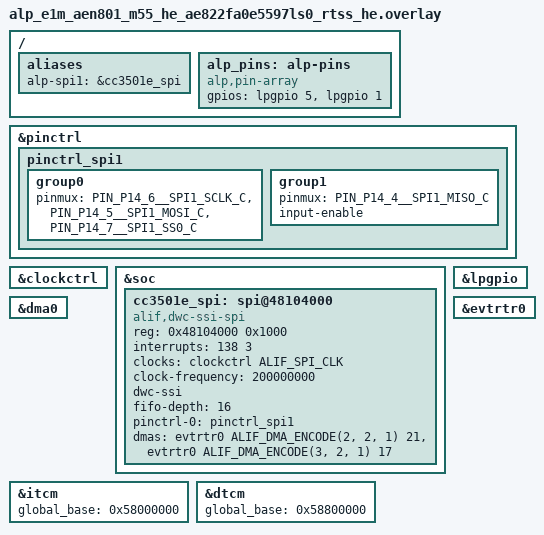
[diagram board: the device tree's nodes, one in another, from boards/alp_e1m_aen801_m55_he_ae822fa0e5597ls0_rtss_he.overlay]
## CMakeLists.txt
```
# SPDX-License-Identifier: Apache-2.0

cmake_minimum_required(VERSION 3.20)

find_package(Zephyr REQUIRED HINTS $ENV{ZEPHYR_BASE})
project(aen_cc3501e_gatt_register LANGUAGES C)

target_sources(app PRIVATE src/main.c)
# Reusable SoM bring-up helper (cc3501e_bridge_bringup): the one-call CC3501E
# bridge init the example + applications use. Copyable template -- see
# cc3501e_bridge.h. (Same helper as aen-cc3501e-companion-tour; examples are
# meant to be self-contained, copyable starting points.)
target_sources(app PRIVATE src/cc3501e_bridge.c)
```

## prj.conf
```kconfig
# SPDX-License-Identifier: Apache-2.0
#
# CONFIG_SPI / CONFIG_GPIO come from board.yaml's `peripherals:` block (via
# the generated alp.conf); CONFIG_RAM_CONSOLE + friends come from
# `diagnostics.console: ram` in the same file -- this file only carries what
# board.yaml has no knob for.
CONFIG_PRINTK=y
CONFIG_LOG=y

# The bench check does a handful of driver scratch buffers (GATT descriptor
# encode + the advertising payload) on the main thread; a generous stack
# keeps them comfortable.
CONFIG_MAIN_STACK_SIZE=4096

# Link the app at the HE MRAM app partition (0x80010000) so its vector table
# matches the ATOC load address (app-zephyr-he.json mramAddress=0x80010000).
# FLASH_BASE is the full MRAM (0x80000000); without this 0x10000 offset the
# image links at 0x80000000 and the SES boots it 64 KB low -> fault/no-boot.
CONFIG_FLASH_LOAD_OFFSET=0x10000
```

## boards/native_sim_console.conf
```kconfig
# SPDX-License-Identifier: Apache-2.0
#
# native_sim override for board.yaml's `diagnostics.console: ram` -- appended
# to EXTRA_CONF_FILE (see CMakeLists.txt) AFTER the generated alp.conf so it
# wins the merge, unlike boards/native_sim_native_64.conf (which Zephyr's own
# board-conf auto-discovery merges BEFORE alp.conf and would just get
# overridden right back to CONFIG_RAM_CONSOLE=y).
#
# native_sim genuinely cannot BUILD CONFIG_RAM_CONSOLE: Zephyr's
# drivers/console/ram_console.c unconditionally calls __stdout_hook_install(),
# and that symbol is only ever DEFINED by a libc integration layer gated
# `depends on !(NATIVE_LIBRARY && EXTERNAL_LIBC)` (lib/libc/Kconfig
# CONFIG_STDOUT_CONSOLE) -- native_sim always selects BOTH NATIVE_LIBRARY and
# EXTERNAL_LIBC, so that guard is always false and the symbol never exists,
# failing the link with "undefined reference to `__stdout_hook_install'".
# The real bench rig has no UART wired to USB, so the RAM console is correct
# there; this file only swaps it back to the native console for the
# native_sim build-only smoke target.
CONFIG_RAM_CONSOLE=n
CONFIG_UART_CONSOLE=y
```

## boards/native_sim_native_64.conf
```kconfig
# SPDX-License-Identifier: Apache-2.0
#
# native_sim has no real SPI controller; pull in the emul SPI driver so
# the alp-spi1 bus enumerates at boot.  Auto-loaded by Zephyr when
# building for native_sim/native/64.  (On the real AEN board the alp-spi1
# alias resolves to the dwc-ssi SPI1 controller instead -- see
# boards/alp_e1m_aen801_m55_he.overlay.)

CONFIG_EMUL=y
CONFIG_SPI_EMUL=y

# NOTE: the RAM-console override for board.yaml's `diagnostics.console: ram`
# is NOT here -- Zephyr's `boards/<board>.conf` auto-discovery merges THIS
# file BEFORE the generated alp.conf (EXTRA_CONF_FILE), so a Kconfig set
# here would just get overwritten by alp.conf's CONFIG_RAM_CONSOLE=y. See
# native_sim_console.conf (merged AFTER alp.conf via testcase.yaml extra_args;
# list it in EXTRA_CONF_FILE) for that override + the reason it's needed.
```

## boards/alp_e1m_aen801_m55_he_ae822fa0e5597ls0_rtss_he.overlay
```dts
/*
 * Copyright (c) 2026 Alp Lab AB
 * SPDX-License-Identifier: Apache-2.0
 *
 * Inter-chip wiring for the CC3501E bring-up on the E1M-AEN801 (Alif
 * Ensemble E8, M55-HE).  Declares the SoM-internal Alif<->CC3501E link:
 * the SPI1 master bus + the two host-driven control nets, all from
 * metadata/e1m_modules/aen/inter-chip.tsv:
 *
 *   SPI1.SCK  P14_6   SPI1.MOSI P14_5   SPI1.MISO P14_4   (-> CC3501E GPIO_27/28/29)
 *   WIFI_EN   P15_5 (lpgpio 5)          E_WIFI.NRST P15_1_FLEX (lpgpio 1)
 *
 * "P15" is the Alif low-power GPIO island (lpgpio @ 0x42002000); the
 * _FLEX pads are its pins.  P14 is a main-domain port used here purely as
 * the SPI1 function via pinctrl, so no gpio14 controller node is needed.
 *
 * BENCH-UNVERIFIED.  Like the rest of the alp-sdk Alif peripheral layer
 * (zephyr/dts/alif/ensemble_e8_peripherals.dtsi), the addresses/IRQs are
 * transcribed from the Apache-2.0 alifsemi/zephyr_alif fork + the AE822
 * TRM and have NOT been validated on silicon.  The SPI1 pinctrl macros are
 * RESOLVED against zephyr/dt-bindings/pinctrl/alif-ensemble-pinctrl.h
 * (SPI1 on P14_4/5/6 = alt-2, the `_C` suffix) and the LP-GPIO mux is the
 * reset default (alt-0 = LPGPIO); the one remaining genuine unknown is the
 * SPI1 IRQ number (upstream Zephyr declares no SPI node, so it is not in
 * the build tree) -- confirm it against the AE822 TRM before relying on
 * the interrupt-driven path on silicon.
 */

#include <zephyr/dt-bindings/pinctrl/alif-ensemble-pinctrl.h>
#include <zephyr/dt-bindings/gpio/gpio.h>
#include <zephyr/dt-bindings/dma/alif_dma_event_router.h>

&pinctrl {
	/*
	 * SPI1 master on P14_6 (SCK) / P14_5 (MOSI) / P14_4 (MISO).
	 *
	 * RESOLVED against alif-ensemble-pinctrl.h: the SPI1 functions on these
	 * three pads are alt-2, named with the `_C` suffix
	 * (PIN_P14_6__SPI1_SCLK_C = ALIF_PINMUX(14, 6, 2), etc.).  input-enable
	 * on MISO so the pad can sense the slave's drive (the same read-enable
	 * requirement the I2C pads need on this SoC).
	 */
	pinctrl_spi1: pinctrl_spi1 {
		group0 {
			/* Hardware SS0 chip-select (P14_7 = SPI1_SS0_C) -- dwc-ssi master
			 * drives SS0 per transfer to frame the CC3501E slave. */
			pinmux = <PIN_P14_6__SPI1_SCLK_C>, <PIN_P14_5__SPI1_MOSI_C>,
				 <PIN_P14_7__SPI1_SS0_C>;
		};
		group1 {
			pinmux = <PIN_P14_4__SPI1_MISO_C>;
			input-enable;
		};
	};
};

/*
 * DWC_ssi SPI1 (AHB) -- the on-SoM CC3501E inter-chip link.  Deliberately
 * NOT in ensemble_e8_peripherals.dtsi (that dtsi declares only the
 * customer-facing edge SPI0); this is the SoM-internal Wi-Fi link, so it
 * lives in the consuming app's overlay.  Same driver + flags as spi0
 * (compatible "alif,dwc-ssi-spi", dwc-ssi layout, fifo-depth 16,
 * frequency-only ALIF_SPI_CLK).
 *
 * reg 0x48104000 = SPI1 base (spi0 is 0x48103000, +0x1000/instance).
 * BENCH-TBD: interrupts = <138 3> follows the consecutive pattern from
 * spi0's IRQ 137 -- confirm SPI1_IRQ against the fork's e1.dtsi / TRM.
 *
 * No cs-gpios: P14_7 is muxed as SPI1_SS0_C above and the dwc-ssi peripheral
 * drives hardware SS0 per transfer.  The host opens ALP_SPI_NO_CS so no GPIO CS
 * is installed, allowing the SPI driver to use its hardware slave-select path.
 */
&clockctrl {
	status = "okay";
};

&soc {
	cc3501e_spi: spi@48104000 {
		compatible = "alif,dwc-ssi-spi";
		#address-cells = <1>;
		#size-cells = <0>;
		reg = <0x48104000 0x1000>;
		interrupts = <138 3>;          /* BENCH-TBD: confirm SPI1 IRQ */
		clocks = <&clockctrl ALIF_SPI_CLK>;
		/*
		 * ROOT-CAUSE FIX 2026-06-16: spi_dw_alif's configure takes the
		 * clock-control path when no clock-frequency is set, and that path
		 * fails (-EINVAL) for the gateless dummy ALIF_SPI_CLK -> every
		 * transceive returned ALP_ERR_INVAL with zero SCLK (witness fail_step=1,
		 * zerr=-EINVAL). Providing the SSI input clock here makes the driver
		 * use it directly and skip the failing clock-control path. SYST_HCLK =
		 * AHB = 400 MHz (E8 HWRM); BAUDR = 400M/freq_hz (=50 for an 8 MHz SCLK).
		 */
		clock-frequency = <200000000>; /* real SSI functional clock (was mis-set 400M; proven via BAUDR scaling) */
		dwc-ssi;
		fifo-depth = <16>;
		pinctrl-0 = <&pinctrl_spi1>;
		pinctrl-names = "default";
		status = "okay";
	};
};

/*
 * Enable the LP GPIO island so WIFI_EN (P15_5) and E_WIFI.NRST
 * (P15_1_FLEX) are drivable as outputs.  gpio_dw needs no clocks/pinctrl
 * on the controller, and the pad->GPIO mux needs no pinctrl group either:
 * RESOLVED against alif-ensemble-pinctrl.h -- P15_1/P15_5 function 0 (the
 * reset default) IS LPGPIO (PIN_P15_x__LPGPIO = ALIF_PINMUX(15, x, 0)).
 */
&lpgpio {
	status = "okay";
};

/* P2_6 (E1M AH7 / I2S1_SCLK) is NOT the CC3501E READY net on the R2 module this
 * bridge targets -- it is E1M pad AH7 / I2S1_SCLK, which the E1M EVK carrier
 * repurposes as the Arduino header's CK_RST (metadata/boards/e1m-evk.yaml);
 * the real READY net lands on E1M pad G3 / IO16 instead
 * (metadata/e1m_modules/aen/from-cc3501e.tsv). This app therefore does not
 * enable &gpio2 or claim P2_6 as READY -- see src/cc3501e_bridge.c and
 * chips/cc3501e/cc3501e_core.c's cc3501e_reply_gate() comment. A board (or a
 * hand-reworked r1 unit) that genuinely wires GPIO17 to P2_6 can opt back
 * in: enable &gpio2, add a pinctrl group that enables P2_6's INPUT BUFFER --
 * reset-default mux already IS GPIO, but GPIO function alone does not enable
 * the input path; skip that group and cc3501e_reply_gate()'s read comes back
 * a constant 0 forever, indistinguishable from a stuck-LOW pad -- add an
 * alp_pins entry for it, and set fw->ready_pin in cc3501e_bridge_bringup(). */

/*
 * Host-side peripheral DMA for continuous SPI streams over the CC3501E bridge.
 * SPI1 is a MAIN-domain peripheral, so per the AE822 DFP soc_dma_map (SPI1_DMA=0,
 * group 2, TX req 21 / RX req 17) it routes through the SYSTOP DMA0 via its event
 * router evtrtr0 (4 groups -> group 2 valid) -- NOT the M55-HE-local DMA2/evtrtr2
 * (1 group, for LP peripherals; wiring SPI1 there leaves the channel Waiting-For-
 * Peripheral forever -- SPI1's request line isn't on the HE router).  DMA0's clock
 * is SYSTOP (already on -- the app drives SPI1/GPIO in the same region); its
 * PL330 boot-manager security latch (CLKCTRL_PER_MST) is in dma_alif_boot_latch.c.
 * The fork PL330 driver statically allocates the per-channel ucode + remaps it via
 * local_to_global(), so no external `microcode` prop is needed.
 *
 * dma0 + evtrtr0 are now declared in ensemble_e8_peripherals.dtsi (disabled
 * by default, alp-sdk issue #1815); this overlay only enables them.
 */
&dma0 {
	status = "okay";
};

&evtrtr0 {
	status = "okay";
};

/*
 * Route the bridge SPI1 through evtrtr0 to DMA0.  Cell encoding
 * (ALIF_DMA_ENCODE(channel, dma_group, handshake), periph_req):
 *   TX = PL330 ch2, evtrtr group 2, handshake on, SPI1 TX periph req 21
 *   RX = PL330 ch3, evtrtr group 2, handshake on, SPI1 RX periph req 17
 * (AE822 DFP soc_dma_map.h: SPI1 group 2, TX 21 / RX 17.)
 */
&cc3501e_spi {
	dmas = <&evtrtr0 ALIF_DMA_ENCODE(2, 2, 1) 21>,
	       <&evtrtr0 ALIF_DMA_ENCODE(3, 2, 1) 17>;
	dma-names = "txdma", "rxdma";
};

/ {
	aliases {
		/* bus_id 1 in alp_spi_open() -> this controller. */
		alp-spi1 = &cc3501e_spi;
	};

	/*
	 * Compact 2-entry control array for the SoM-internal CC3501E control
	 * nets, in the order the app's CC3501E_PIN_* indices expect.  These are
	 * NOT E1M edge pads, so this bring-up app intentionally does NOT use the
	 * 52-slot positional E1M map; a production board file appends such
	 * SoM-internal control nets after the E1M pad slots.  No READY entry
	 * here -- see the P2_6 comment above &gpio2's removal further up.
	 */
	alp_pins: alp-pins {
		compatible = "alp,pin-array";
		gpios = <&lpgpio 5 GPIO_ACTIVE_HIGH>, /* [0] WIFI_EN     (P15_5)      */
			<&lpgpio 1 GPIO_ACTIVE_HIGH>; /* [1] E_WIFI.NRST (P15_1_FLEX) */
	};
};

/*
 * Global-bus aliases of the M55-HE TCMs, needed by hal_alif soc_memory_map.h
 * local_to_global() -- the PL330 (AXI master) reaches TCM-resident buffers only
 * via these global windows.  Values from the AE822 M55-HE map (sdk-alif fork
 * ensemble_rtss_he.dtsi): ITCM 0x0->0x58000000, DTCM 0x20000000->0x58800000.
 * (DMA stream buffers still belong in SRAM0 0x02000000, which is already global
 * -> local_to_global() returns it unchanged.)
 */
&itcm {
	global_base = <0x58000000>;
};
&dtcm {
	global_base = <0x58800000>;
};
```

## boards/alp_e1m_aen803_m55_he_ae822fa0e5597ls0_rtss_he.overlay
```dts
/*
 * Copyright (c) 2026 Alp Lab AB
 * SPDX-License-Identifier: Apache-2.0
 *
 * Inter-chip wiring for the CC3501E bring-up on the E1M-AEN803 (Alif
 * Ensemble E8, M55-HE).  Declares the SoM-internal Alif<->CC3501E link:
 * the SPI1 master bus + the two host-driven control nets, all from
 * metadata/e1m_modules/aen/inter-chip.tsv:
 *
 *   SPI1.SCK  P14_6   SPI1.MOSI P14_5   SPI1.MISO P14_4   (-> CC3501E GPIO_27/28/29)
 *   WIFI_EN   P15_5 (lpgpio 5)          E_WIFI.NRST P15_1_FLEX (lpgpio 1)
 *
 * "P15" is the Alif low-power GPIO island (lpgpio @ 0x42002000); the
 * _FLEX pads are its pins.  P14 is a main-domain port used here purely as
 * the SPI1 function via pinctrl, so no gpio14 controller node is needed.
 *
 * BENCH-UNVERIFIED.  Like the rest of the alp-sdk Alif peripheral layer
 * (zephyr/dts/alif/ensemble_e8_peripherals.dtsi), the addresses/IRQs are
 * transcribed from the Apache-2.0 alifsemi/zephyr_alif fork + the AE822
 * TRM and have NOT been validated on silicon.  The SPI1 pinctrl macros are
 * RESOLVED against zephyr/dt-bindings/pinctrl/alif-ensemble-pinctrl.h
 * (SPI1 on P14_4/5/6 = alt-2, the `_C` suffix) and the LP-GPIO mux is the
 * reset default (alt-0 = LPGPIO); the one remaining genuine unknown is the
 * SPI1 IRQ number (upstream Zephyr declares no SPI node, so it is not in
 * the build tree) -- confirm it against the AE822 TRM before relying on
 * the interrupt-driven path on silicon.
 */

#include <zephyr/dt-bindings/pinctrl/alif-ensemble-pinctrl.h>
#include <zephyr/dt-bindings/gpio/gpio.h>
#include <zephyr/dt-bindings/dma/alif_dma_event_router.h>

&pinctrl {
	/*
	 * SPI1 master on P14_6 (SCK) / P14_5 (MOSI) / P14_4 (MISO).
	 *
	 * RESOLVED against alif-ensemble-pinctrl.h: the SPI1 functions on these
	 * three pads are alt-2, named with the `_C` suffix
	 * (PIN_P14_6__SPI1_SCLK_C = ALIF_PINMUX(14, 6, 2), etc.).  input-enable
	 * on MISO so the pad can sense the slave's drive (the same read-enable
	 * requirement the I2C pads need on this SoC).
	 */
	pinctrl_spi1: pinctrl_spi1 {
		group0 {
			/* Hardware SS0 chip-select (P14_7 = SPI1_SS0_C) -- dwc-ssi master
			 * drives SS0 per transfer to frame the CC3501E slave. */
			pinmux = <PIN_P14_6__SPI1_SCLK_C>, <PIN_P14_5__SPI1_MOSI_C>,
				 <PIN_P14_7__SPI1_SS0_C>;
		};
		group1 {
			pinmux = <PIN_P14_4__SPI1_MISO_C>;
			input-enable;
		};
	};
};

/*
 * DWC_ssi SPI1 (AHB) -- the on-SoM CC3501E inter-chip link.  Deliberately
 * NOT in ensemble_e8_peripherals.dtsi (that dtsi declares only the
 * customer-facing edge SPI0); this is the SoM-internal Wi-Fi link, so it
 * lives in the consuming app's overlay.  Same driver + flags as spi0
 * (compatible "alif,dwc-ssi-spi", dwc-ssi layout, fifo-depth 16,
 * frequency-only ALIF_SPI_CLK).
 *
 * reg 0x48104000 = SPI1 base (spi0 is 0x48103000, +0x1000/instance).
 * BENCH-TBD: interrupts = <138 3> follows the consecutive pattern from
 * spi0's IRQ 137 -- confirm SPI1_IRQ against the fork's e1.dtsi / TRM.
 *
 * No cs-gpios: P14_7 is muxed as SPI1_SS0_C above and the dwc-ssi peripheral
 * drives hardware SS0 per transfer.  The host opens ALP_SPI_NO_CS so no GPIO CS
 * is installed, allowing the SPI driver to use its hardware slave-select path.
 */
&clockctrl {
	status = "okay";
};

&soc {
	cc3501e_spi: spi@48104000 {
		compatible = "alif,dwc-ssi-spi";
		#address-cells = <1>;
		#size-cells = <0>;
		reg = <0x48104000 0x1000>;
		interrupts = <138 3>;          /* BENCH-TBD: confirm SPI1 IRQ */
		clocks = <&clockctrl ALIF_SPI_CLK>;
		/*
		 * ROOT-CAUSE FIX 2026-06-16: spi_dw_alif's configure takes the
		 * clock-control path when no clock-frequency is set, and that path
		 * fails (-EINVAL) for the gateless dummy ALIF_SPI_CLK -> every
		 * transceive returned ALP_ERR_INVAL with zero SCLK (witness fail_step=1,
		 * zerr=-EINVAL). Providing the SSI input clock here makes the driver
		 * use it directly and skip the failing clock-control path. SYST_HCLK =
		 * AHB = 400 MHz (E8 HWRM); BAUDR = 400M/freq_hz (=50 for an 8 MHz SCLK).
		 */
		clock-frequency = <200000000>; /* real SSI functional clock (was mis-set 400M; proven via BAUDR scaling) */
		dwc-ssi;
		fifo-depth = <16>;
		pinctrl-0 = <&pinctrl_spi1>;
		pinctrl-names = "default";
		status = "okay";
	};
};

/*
 * Enable the LP GPIO island so WIFI_EN (P15_5) and E_WIFI.NRST
 * (P15_1_FLEX) are drivable as outputs.  gpio_dw needs no clocks/pinctrl
 * on the controller, and the pad->GPIO mux needs no pinctrl group either:
 * RESOLVED against alif-ensemble-pinctrl.h -- P15_1/P15_5 function 0 (the
 * reset default) IS LPGPIO (PIN_P15_x__LPGPIO = ALIF_PINMUX(15, x, 0)).
 */
&lpgpio {
	status = "okay";
};

/* P2_6 (E1M AH7 / I2S1_SCLK) is NOT the CC3501E READY net on the R2 module this
 * bridge targets -- it is E1M pad AH7 / I2S1_SCLK, which the E1M EVK carrier
 * repurposes as the Arduino header's CK_RST (metadata/boards/e1m-evk.yaml);
 * the real READY net lands on E1M pad G3 / IO16 instead
 * (metadata/e1m_modules/aen/from-cc3501e.tsv). This app therefore does not
 * enable &gpio2 or claim P2_6 as READY -- see src/cc3501e_bridge.c and
 * chips/cc3501e/cc3501e_core.c's cc3501e_reply_gate() comment. A board (or a
 * hand-reworked r1 unit) that genuinely wires GPIO17 to P2_6 can opt back
 * in: enable &gpio2, add a pinctrl group that enables P2_6's INPUT BUFFER --
 * reset-default mux already IS GPIO, but GPIO function alone does not enable
 * the input path; skip that group and cc3501e_reply_gate()'s read comes back
 * a constant 0 forever, indistinguishable from a stuck-LOW pad -- add an
 * alp_pins entry for it, and set fw->ready_pin in cc3501e_bridge_bringup(). */

/*
 * Host-side peripheral DMA for continuous SPI streams over the CC3501E bridge.
 * SPI1 is a MAIN-domain peripheral, so per the AE822 DFP soc_dma_map (SPI1_DMA=0,
 * group 2, TX req 21 / RX req 17) it routes through the SYSTOP DMA0 via its event
 * router evtrtr0 (4 groups -> group 2 valid) -- NOT the M55-HE-local DMA2/evtrtr2
 * (1 group, for LP peripherals; wiring SPI1 there leaves the channel Waiting-For-
 * Peripheral forever -- SPI1's request line isn't on the HE router).  DMA0's clock
 * is SYSTOP (already on -- the app drives SPI1/GPIO in the same region); its
 * PL330 boot-manager security latch (CLKCTRL_PER_MST) is in dma_alif_boot_latch.c.
 * The fork PL330 driver statically allocates the per-channel ucode + remaps it via
 * local_to_global(), so no external `microcode` prop is needed.
 *
 * dma0 + evtrtr0 are now declared in ensemble_e8_peripherals.dtsi (disabled
 * by default, alp-sdk issue #1815); this overlay only enables them.
 */
&dma0 {
	status = "okay";
};

&evtrtr0 {
	status = "okay";
};

/*
 * Route the bridge SPI1 through evtrtr0 to DMA0.  Cell encoding
 * (ALIF_DMA_ENCODE(channel, dma_group, handshake), periph_req):
 *   TX = PL330 ch2, evtrtr group 2, handshake on, SPI1 TX periph req 21
 *   RX = PL330 ch3, evtrtr group 2, handshake on, SPI1 RX periph req 17
 * (AE822 DFP soc_dma_map.h: SPI1 group 2, TX 21 / RX 17.)
 */
&cc3501e_spi {
	dmas = <&evtrtr0 ALIF_DMA_ENCODE(2, 2, 1) 21>,
	       <&evtrtr0 ALIF_DMA_ENCODE(3, 2, 1) 17>;
	dma-names = "txdma", "rxdma";
};

/ {
	aliases {
		/* bus_id 1 in alp_spi_open() -> this controller. */
		alp-spi1 = &cc3501e_spi;
	};

	/*
	 * Compact 2-entry control array for the SoM-internal CC3501E control
	 * nets, in the order the app's CC3501E_PIN_* indices expect.  These are
	 * NOT E1M edge pads, so this bring-up app intentionally does NOT use the
	 * 52-slot positional E1M map; a production board file appends such
	 * SoM-internal control nets after the E1M pad slots.  No READY entry
	 * here -- see the P2_6 comment above &gpio2's removal further up.
	 */
	alp_pins: alp-pins {
		compatible = "alp,pin-array";
		gpios = <&lpgpio 5 GPIO_ACTIVE_HIGH>, /* [0] WIFI_EN     (P15_5)      */
			<&lpgpio 1 GPIO_ACTIVE_HIGH>; /* [1] E_WIFI.NRST (P15_1_FLEX) */
	};
};

/*
 * Global-bus aliases of the M55-HE TCMs, needed by hal_alif soc_memory_map.h
 * local_to_global() -- the PL330 (AXI master) reaches TCM-resident buffers only
 * via these global windows.  Values from the AE822 M55-HE map (sdk-alif fork
 * ensemble_rtss_he.dtsi): ITCM 0x0->0x58000000, DTCM 0x20000000->0x58800000.
 * (DMA stream buffers still belong in SRAM0 0x02000000, which is already global
 * -> local_to_global() returns it unchanged.)
 */
&itcm {
	global_base = <0x58000000>;
};
&dtcm {
	global_base = <0x58800000>;
};
```

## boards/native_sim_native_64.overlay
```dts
/*
 * Copyright 2026 Alp Lab AB
 * SPDX-License-Identifier: Apache-2.0
 *
 * Host-emulated stand-ins for aen-cc3501e-bringup under native_sim, so the
 * example builds in CI (twister build_only) with no silicon.
 *
 *   - alp-spi1  -> an emulated SPI controller (no slave attached, so the
 *                  transceive path runs but reads back 0x00; the build, not
 *                  a live round-trip, is what this target proves).
 *   - alp,pin-array -> the two SoM-internal CC3501E control nets, in the
 *                  SAME order the app's CC3501E_PIN_* indices expect:
 *                    [0] WIFI_EN  (Alif P15_5)
 *                    [1] E_WIFI.NRST (Alif P15_1_FLEX)
 *                  This bring-up app uses its own compact 2-pin control
 *                  array (these nets are not E1M edge pads), not the 52-slot
 *                  positional E1M map the portable IO examples use.
 */

#include <zephyr/dt-bindings/gpio/gpio.h>

/ {
    aliases {
        alp-spi1 = &spi1_emul;
    };

    gpio_emul0: gpio_emul0 {
        compatible = "zephyr,gpio-emul";
        status = "okay";
        gpio-controller;
        rising-edge;
        falling-edge;
        #gpio-cells = <2>;
        ngpios = <8>;
    };

    alp_pins: alp-pins {
        compatible = "alp,pin-array";
        gpios = <&gpio_emul0 5 GPIO_ACTIVE_HIGH>,   /* [0] WIFI_EN     (P15_5)      */
                <&gpio_emul0 1 GPIO_ACTIVE_HIGH>;   /* [1] E_WIFI.NRST (P15_1_FLEX) */
    };

    soc {
        spi1_emul: spi@200 {
            compatible = "zephyr,spi-emul-controller";
            status = "okay";
            reg = <0 0x200 4>;
            #address-cells = <1>;
            #size-cells = <0>;
        };
    };
};
```

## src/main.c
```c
/*
 * Copyright 2026 Alp Lab AB
 * SPDX-License-Identifier: Apache-2.0
 *
 * aen-cc3501e-gatt-register -- bench check for the NEW CC3501E dynamic GATT
 * registration path (#480/#892) on the Alif Ensemble E8 (M55-HE).
 *
 * WHAT CHANGED UPSTREAM.  `alp_ble_gatt_register_service()` used to be a
 * stub; on this branch it really registers a service on the CC3501E's
 * NimBLE host over the inter-chip bridge and fills in a real attribute
 * handle per characteristic.  This app is the on-silicon proof, run
 * PEER-FREE -- there is no BLE central on the bench, so it cannot do full
 * central-side service discovery.  What it CAN prove without a peer:
 *
 *   1. registration returns real (non-zero) handles -- the registration
 *      itself worked, not just "the call didn't crash";
 *   2. the bridge is still alive and answering AFTER registration -- the
 *      on-silicon check for a NimBLE double-`ble_gatts_start()` use-after-
 *      free that the register path used to trigger (now fixed by resetting
 *      the GATT table via a single `ble_gatts_start()` per register, not a
 *      stray extra call);
 *   3. the register-then-advertise ORDERING GUARD: NimBLE's
 *      `ble_gatts_mutable()` refuses to re-run `ble_gatts_start()` once the
 *      stack is advertising/scanning/connected, so a SECOND register call
 *      issued while advertising must come back `ALP_ERR_BUSY` (see the
 *      @note on `alp_ble_gatt_register_service()` in <alp/ble.h>, and the
 *      wire-level remap comment in chips/cc3501e/cc3501e_ble.c).
 *
 * Full central-side verification (a real central connecting and reading
 * the two characteristics by their discovered handles) is HIL-deferred --
 * it needs a second BLE radio on the bench, which this rig does not have.
 *
 * THE SIX-STEP PASS CONTRACT (order matters -- register must precede
 * advertise, per the @note above):
 *
 *   1. cc3501e_bridge_bringup() + PING -> ALP_OK           (bridge ready)
 *   2. alp_ble_open()            -> non-NULL               (BLE enabled)
 *   3. alp_ble_gatt_register_service() (2 chars)
 *        -> ALP_OK AND both handles non-zero                (registered)
 *   4. a second bridge round-trip (PING) post-register
 *        -> still ALP_OK                                    (UAF-fix check)
 *   5. alp_ble_advertise_start() (<=8-char name)
 *        -> ALP_OK                                          (advertising)
 *   6. alp_ble_gatt_register_service() AGAIN, while advertising
 *        -> ALP_ERR_BUSY                                     (ordering guard)
 *
 * A single `RESULT PASS: ...` line means every step above held; the first
 * step that didn't prints `RESULT FAIL: <which step>` and the app stops --
 * this is a bench GATE, unlike the companion-tour's guarded non-fatal demo
 * steps.
 *
 * Console is the RAM buffer `ram_console_buf` (board.yaml `diagnostics.console:
 * ram`); this bench rig has no UART wired to USB.  BENCH-VALIDATION app --
 * not a customer teaching example (see aen-cc3501e-companion-tour for that).
 *
 * This file is ~50% comment by design: examples are documentation, and a
 * bench-gate app doubles as the readable spec of what "the fix works" means.
 */

#include <stdbool.h>
#include <stdio.h>

#include <zephyr/kernel.h> /* k_uptime_get() -- step-6 fast-path timing */

#include "alp/ble.h"
#include "alp/chips/cc3501e.h"
#include "alp/peripheral.h"

#include "cc3501e_bridge.h" /* cc3501e_bridge_bringup() -- the SoM bring-up helper */

/* Poll-by-repeat budgets.  PING is cheap + direct (see cc3501e_ping's doc);
 * a handful of retries absorbs residual boot/ramp jitter after
 * cc3501e_bridge_bringup() already waited out the fixed boot budget. */
#define GATT_PING_RETRIES 25u
#define GATT_PING_GAP_MS  200u

/*
 * Example-only vendor 128-bit service + characteristic UUIDs (bytes are
 * little-endian per alp_ble_uuid_t's doc comment).  These are NOT a
 * registered BT-SIG UUID -- a real product picks its own random 128-bit
 * UUID per service (e.g. `uuidgen`).  Three distinct UUIDs, one per
 * service/characteristic, differing only in the last two bytes so the
 * relationship is easy to eyeball in a hex dump.
 */
static const alp_ble_uuid_t GATT_SVC_UUID = { .b = { 0x01,
	                                                 0x02,
	                                                 0x03,
	                                                 0x04,
	                                                 0x05,
	                                                 0x06,
	                                                 0x07,
	                                                 0x08,
	                                                 0x09,
	                                                 0x0a,
	                                                 0x0b,
	                                                 0x0c,
	                                                 0x0d,
	                                                 0x0e,
	                                                 0xa0,
	                                                 0xa1 } };

static const alp_ble_uuid_t GATT_CHR_RO_UUID = { .b = { 0x01,
	                                                    0x02,
	                                                    0x03,
	                                                    0x04,
	                                                    0x05,
	                                                    0x06,
	                                                    0x07,
	                                                    0x08,
	                                                    0x09,
	                                                    0x0a,
	                                                    0x0b,
	                                                    0x0c,
	                                                    0x0d,
	                                                    0x0e,
	                                                    0xb0,
	                                                    0xb1 } };

static const alp_ble_uuid_t GATT_CHR_NOTIFY_UUID = { .b = { 0x01,
	                                                        0x02,
	                                                        0x03,
	                                                        0x04,
	                                                        0x05,
	                                                        0x06,
	                                                        0x07,
	                                                        0x08,
	                                                        0x09,
	                                                        0x0a,
	                                                        0x0b,
	                                                        0x0c,
	                                                        0x0d,
	                                                        0x0e,
	                                                        0xc0,
	                                                        0xc1 } };

/* Small initial values -- just enough bytes to prove the descriptor encode
 * (chips/cc3501e/cc3501e_ble.c's cc35_gatt_register_service) round-trips
 * non-empty payloads, not a real sensor reading. */
static const uint8_t GATT_REG_RO_INITIAL[]     = { 0x2a };
static const uint8_t GATT_REG_NOTIFY_INITIAL[] = { 0x00 };

/* Step: PING until the coprocessor answers (or the retry budget elapses).
 * Used both for the initial link-up check (step 1) and the post-register
 * liveness check (step 4) -- same helper, different meaning at each call
 * site (see the call sites below). */
static bool gatt_ping(cc3501e_t *fw)
{
	for (unsigned i = 0u; i < GATT_PING_RETRIES; ++i) {
		if (cc3501e_ping(fw) == ALP_OK) {
			return true;
		}
		alp_delay_ms(GATT_PING_GAP_MS);
	}
	return false;
}

int main(void)
{
	printf("\n[gatt-register] E1M-AEN CC3501E dynamic GATT registration bench check\n");

	/* ---- Step 1: bridge bring-up + PING -------------------------------- */
	cc3501e_t    fw;
	alp_status_t s = cc3501e_bridge_bringup(&fw);
	if (s != ALP_OK) {
		printf("RESULT FAIL: step 1 bridge bring-up -> %s (check WIFI_EN/SPI1 wiring)\n",
		       alp_status_name(s));
		return 0;
	}
	if (!gatt_ping(&fw)) {
		printf("RESULT FAIL: step 1 PING never answered after bring-up\n");
		return 0;
	}
	printf("[gatt-register] step 1 OK: bridge up + PING answered\n");

	/* ---- Step 2: alp_ble_open() ----------------------------------------
	 * The CC3501E BLE backend's open() (src/backends/ble/cc3501e.c
	 * cc35_open) calls cc3501e_ble_enable() on the first reference, which
	 * starts the firmware's shared-HIF Wi-Fi stack then the NimBLE host --
	 * a non-NULL return here means BOTH came up. */
	alp_ble_t *ble = alp_ble_open();
	if (ble == NULL) {
		printf("RESULT FAIL: step 2 alp_ble_open() -> NULL (err=%s)\n",
		       alp_status_name(alp_last_error()));
		return 0;
	}
	printf("[gatt-register] step 2 OK: alp_ble_open() -> %p (BLE controller + NimBLE up)\n",
	       (void *)ble);

	/* ---- Step 3: register a 2-characteristic service --------------------
	 * READ char first (a passive attribute), READ|NOTIFY second (the one a
	 * real central would subscribe to). Register-before-advertise is the
	 * hard ordering rule this whole app exists to prove -- see the file
	 * banner. A non-zero handle in BOTH slots is the only proof (short of a
	 * central connecting) that the firmware's NimBLE host actually built
	 * GATT attribute-table entries instead of silently no-op'ing. */
	alp_ble_char_def_t chars[2] = {
		{
		    .uuid          = GATT_CHR_RO_UUID,
		    .properties    = ALP_BLE_GATT_PROP_READ,
		    .initial_value = GATT_REG_RO_INITIAL,
		    .initial_len   = sizeof(GATT_REG_RO_INITIAL),
		},
		{
		    .uuid          = GATT_CHR_NOTIFY_UUID,
		    .properties    = ALP_BLE_GATT_PROP_READ | ALP_BLE_GATT_PROP_NOTIFY,
		    .initial_value = GATT_REG_NOTIFY_INITIAL,
		    .initial_len   = sizeof(GATT_REG_NOTIFY_INITIAL),
		},
	};
	alp_ble_service_def_t def = {
		.service_uuid = GATT_SVC_UUID,
		.chars        = chars,
		.num_chars    = 2u,
	};
	alp_ble_attr_handle_t handles[2] = { 0u, 0u };
	s                                = alp_ble_gatt_register_service(ble, &def, handles);
	if (s != ALP_OK || handles[0] == 0u || handles[1] == 0u) {
		printf("RESULT FAIL: step 3 alp_ble_gatt_register_service() -> %s "
		       "handles=[0x%04x, 0x%04x]\n",
		       alp_status_name(s),
		       handles[0],
		       handles[1]);
		alp_ble_close(ble);
		return 0;
	}
	printf("[gatt-register] step 3 OK: registered -- handles=[0x%04x, 0x%04x]\n",
	       handles[0],
	       handles[1]);

	/* ---- Step 4: post-register bridge liveness (the UAF-fix proof) ------
	 * The firmware's register handler re-runs ble_gatts_start() (via
	 * ble_gatts_reset()) to rebuild the attribute table.  Before this
	 * branch's fix, a second/duplicate ble_gatts_start() call could leave
	 * a stale pointer live in the NimBLE heap -- with that bug, the NEXT
	 * bridge transaction (this PING) is exactly where it would surface: as
	 * a desync/hang instead of a clean reply.  A live, correct bridge just
	 * answers PING here, same as step 1.  This is peer-free by design --
	 * it doesn't need a central, only a second round-trip after register. */
	if (!gatt_ping(&fw)) {
		printf("RESULT FAIL: step 4 post-register PING never answered -- possible bridge "
		       "desync/hang (the double-ble_gatts_start() UAF this app checks for)\n");
		alp_ble_close(ble);
		return 0;
	}
	printf("[gatt-register] step 4 OK: bridge still alive post-register (UAF-fix check "
	       "passed)\n");

	/* ---- Step 5: start advertising --------------------------------------
	 * Name budget: the CC3501E backend's pack_adv_data() (src/backends/ble/
	 * cc3501e.c) packs Flags (3 bytes: 1 length + 1 type + 1 flags byte),
	 * then the local name (2 + strlen bytes), then any advertised service
	 * UUIDs (2 + 16*count bytes), into a 31-byte legacy adv PDU
	 * (BLE_AD_MAX_LEN).  We advertise our own registered service UUID
	 * alongside an 8-char name: 3 + (2+8) + (2+16) = 31 -- exactly at the
	 * budget, not over it. A longer name (or a 2nd advertised UUID) would
	 * overflow and pack_adv_data() would return ALP_ERR_INVAL. */
	alp_ble_adv_config_t adv = ALP_BLE_ADV_CONFIG_DEFAULT("GattTest");
	adv.services             = &GATT_SVC_UUID;
	adv.num_services         = 1u;
	s                        = alp_ble_advertise_start(ble, &adv);
	if (s != ALP_OK) {
		printf("RESULT FAIL: step 5 alp_ble_advertise_start() -> %s\n", alp_status_name(s));
		alp_ble_close(ble);
		return 0;
	}
	printf("[gatt-register] step 5 OK: advertising as \"%s\"\n", adv.name);

	/* ---- Step 6: a SECOND register -> must be BUSY, PROMPTLY ---------------
	 * Step 3 already registered a service, and v1 firmware allows one dynamic
	 * service per boot, so this second register is a DETERMINISTIC wrong-state
	 * reject (the same class as registering while advertising, which NimBLE's
	 * ble_gatts_mutable() guard also refuses).  The firmware returns the
	 * distinct wire status ALP_CC3501E_RESP_ERR_STATE (0x09), which
	 * chips/cc3501e/cc3501e_ble.c maps to a TERMINAL ALP_ERR_BUSY --
	 * poll_by_repeat returns it immediately (one round trip) instead of
	 * retrying across the full op-timeout budget.  So this must come back BUSY
	 * *promptly*, not after several seconds.  We time it: a multi-second
	 * return would mean the distinct-status fast-path did not engage (the old
	 * -1-misclassified-as-IO budget-burn). */
	alp_ble_attr_handle_t handles2[2] = { 0u, 0u };
	int64_t               t0          = k_uptime_get();
	s                                 = alp_ble_gatt_register_service(ble, &def, handles2);
	int64_t elapsed_ms                = k_uptime_get() - t0;
	if (s != ALP_ERR_BUSY) {
		printf("RESULT FAIL: step 6 register-while-advertising -> %s (expected "
		       "ALP_ERR_BUSY -- the ble_gatts_mutable() ordering guard didn't trip)\n",
		       alp_status_name(s));
		alp_ble_close(ble);
		return 0;
	}
	if (elapsed_ms > 2000) {
		printf("RESULT FAIL: step 6 returned ALP_ERR_BUSY but took %lld ms -- the terminal "
		       "RESP_ERR_STATE fast-path did not engage (budget-burn regression)\n",
		       (long long)elapsed_ms);
		alp_ble_close(ble);
		return 0;
	}
	printf("[gatt-register] step 6 OK: register-while-advertising -> ALP_ERR_BUSY in %lld ms "
	       "(prompt terminal reject, fast-path engaged)\n",
	       (long long)elapsed_ms);

	alp_ble_close(ble);
	printf("RESULT PASS: register(handles=[0x%04x,0x%04x]) -> post-register PING alive -> "
	       "advertise -> register-while-advertising -> ALP_ERR_BUSY\n",
	       handles[0],
	       handles[1]);
	return 0;
}
```

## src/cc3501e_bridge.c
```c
/*
 * SPDX-License-Identifier: Apache-2.0
 * Copyright 2026 Alp Lab AB
 *
 * E1M-AEN SoM CC3501E bridge bring-up helper -- see cc3501e_bridge.h.
 *
 * The final reset is warm-aware.  cc3501e_reset() drops WIFI_EN for 50 ms, a
 * supply cold cycle; on a CC3501E that is already running (an activated unit with
 * vendor_sbl_container_enable=1 may then never relaunch) that must not happen on a
 * mere re-run or warm reset of the application.  So when WIFI_EN already reads high
 * AND the chip answers a PING the bring-up resets through nRESET only
 * (cc3501e_hard_reset()), and uses cc3501e_reset() only from WIFI_EN low or, as a
 * last resort, from a chip that stays silent through an nRESET-only reset.  WIFI_EN
 * reading high alone is not trusted: a pull-up would make every power-on look warm
 * (whether the module has one is an open question, issue #2797).
 */

#include "cc3501e_bridge.h"

#include <stdio.h>

#if defined(CONFIG_SOC_AE822FA0E5597LS0_RTSS_HE) || defined(CONFIG_SOC_AE822FA0E5597LS0_RTSS_HP)
#include <zephyr/arch/cpu.h>
#include <zephyr/device.h>
#include <zephyr/drivers/gpio.h>
#include <zephyr/sys/sys_io.h>
/*
 * AEN LP-pad mux (Alif Ensemble E8, both M55-HE and M55-HP cores).  WIFI_EN
 * (P15_5) and nRESET (P15_1) are on the Alif LP-GPIO island, bound by the
 * generic snps,designware-gpio driver which does NOT apply Alif pinctrl --
 * so the LP pads stay un-muxed and their output drivers OFF (confirmed on
 * silicon on M55-HE: WIFI_EN never powers the CC3501E until these regs are
 * set).  0x23 = the Alif GPIO-output pad config (driver + read-enable +
 * drive strength).  TODO: drop this raw poke once the Alif GPIO backend
 * muxes the LP island via pinctrl.
 *
 * ALIF_LPGPIO_PADCTRL_BASE (0x42007000) is not an M55-HE-local address: the
 * shared upstream `pin-controller@1a603000` node (ensemble_common.dtsi,
 * included by both cores' SoC dtsi) declares this exact window as its
 * second `reg` range, and `alp_e1m_aen801_m55_hp-pinctrl.dtsi` already
 * muxes a different LP-GPIO pad (P15_0, RTC_ALARM) from the M55-HP pinctrl
 * driver through it, so the poke below is equally applicable on M55-HP.
 * Running it on M55-HP is NOT bench-proven -- only running it on M55-HE has
 * been confirmed on silicon.
 */
#define ALIF_LPGPIO_PADCTRL_BASE 0x42007000u
#define ALIF_PAD_GPIO_OUTPUT     0x23u
/* Latch WIFI_EN (P15_5) HIGH in the port's data register while the pad is still an
 * INPUT.  Switching the direction afterwards then drives the already-high level; the
 * other order (direction first, value second -- what gpio_dw's configure does even
 * with an init flag) drives whatever DR holds, and with DR bit 5 = 0 that glitches
 * the supply of a running chip low.  gpio_port_set_bits_raw() writes DR regardless
 * of direction. */
static void aen_wifi_en_latch_high(void)
{
	const struct device *lpgpio = DEVICE_DT_GET(DT_NODELABEL(lpgpio));

	if (device_is_ready(lpgpio)) {
		(void)gpio_port_set_bits_raw(lpgpio, BIT(5));
	}
}

static void aen_lp_pads_enable_output(void)
{
	sys_write32(ALIF_PAD_GPIO_OUTPUT, ALIF_LPGPIO_PADCTRL_BASE + 5u * 4u); /* P15_5 WIFI_EN */
	sys_write32(ALIF_PAD_GPIO_OUTPUT, ALIF_LPGPIO_PADCTRL_BASE + 1u * 4u); /* P15_1 nRESET  */
}
#else
static inline void aen_lp_pads_enable_output(void)
{
}
static inline void aen_wifi_en_latch_high(void)
{
}
#endif

alp_status_t cc3501e_bridge_bringup(cc3501e_t *fw)
{
	if (fw == NULL) {
		return ALP_ERR_INVAL;
	}

	/* 1. Control pins: WIFI_EN (supply gate) + nRESET.  These are Alif LP-GPIO
	 *    pads, not E1M edge pads -- the SoM owns them. */
	alp_gpio_t *wifi_en = alp_gpio_open(CC3501E_BRIDGE_PIN_WIFI_EN);
	alp_gpio_t *nrst    = alp_gpio_open(CC3501E_BRIDGE_PIN_NRST);
	if (wifi_en == NULL || nrst == NULL) {
		if (wifi_en != NULL) {
			alp_gpio_close(wifi_en);
		}
		if (nrst != NULL) {
			alp_gpio_close(nrst);
		}
		return ALP_ERR_NOT_PRESENT_ON_THIS_SOC;
	}
	aen_lp_pads_enable_output();
	/* Sample the supply gate BEFORE touching its direction.  High is only a HINT
	 * that the chip may be powered -- an external pull-up on WIFI_EN would make every
	 * power-on read high (whether the module has one is an OPEN QUESTION; the
	 * netlist has not been checked), so the decision below also needs a PING. */
	bool wifi_was_high = false;
	(void)alp_gpio_read(wifi_en, &wifi_was_high);
	if (wifi_was_high) {
		/* Latch the level in DR first so the direction change cannot glitch it low. */
		aen_wifi_en_latch_high();
	}
	(void)alp_gpio_configure(wifi_en, ALP_GPIO_OUTPUT, ALP_GPIO_PULL_NONE);
	(void)alp_gpio_configure(nrst, ALP_GPIO_OUTPUT, ALP_GPIO_PULL_NONE);

	/* 2. Inter-chip SPI (Alif = master).  CS is the dwc-ssi hardware SS0
	 *    muxed on P14_7; the app passes ALP_SPI_NO_CS so no software GPIO CS
	 *    is installed and the SPI controller drives SS0 per transfer.  Mode 0
	 *    matches the CC3501E vendor image frameFormat. */
	alp_spi_t *spi = alp_spi_open(&(alp_spi_config_t){
	    .bus_id        = CC3501E_BRIDGE_SPI_BUS_ID,
	    .freq_hz       = CC3501E_BRIDGE_SPI_FREQ_HZ,
	    .mode          = ALP_SPI_MODE_0,
	    .bits_per_word = 8u,
	    .cs_pin_id     = ALP_SPI_NO_CS,
	});
	if (spi == NULL) {
		alp_gpio_close(wifi_en);
		alp_gpio_close(nrst);
		return ALP_ERR_NOT_PRESENT_ON_THIS_SOC;
	}

#if CC3501E_BRIDGE_RX_SAMPLE_DLY > 0
	/* Raise the SCLK past 1 MHz: the DW SSI RX_SAMPLE_DLY register (0xf0) delays
	 * the MISO capture point by N ssi_clk cycles to cover the on-SoM trace + crossed
	 * data round-trip.  Zephyr spi_dw never writes it (leaves 0), so without this
	 * >1 MHz mis-samples MISO (cold reqhdr_rx=0xFFFFFFFF).  Written with SSI disabled
	 * (SSIENR=0); persists across the driver's per-transfer configure.  Value is
	 * silicon-tuned -- sweep CC3501E_BRIDGE_RX_SAMPLE_DLY at the target SCLK.
	 *
	 * SWEEP TRAP -- read before setting the constant to 0: the `#if > 0` above
	 * compiles this block out, so 0 does not mean "no delay", it means the SPI
	 * node's `rx-delay` devicetree value is left in place.  aen-cc3501e-bringup
	 * and aen-evk-demo declare rx-delay = <2>, so a naive N=0 sweep point on
	 * those two silently measures 2.  Read 0x481040F0 back to see what the link
	 * is actually running at. */
	{
		volatile uint32_t *ssienr =
		    (volatile uint32_t *)(uintptr_t)(CC3501E_BRIDGE_SPI1_BASE + 0x08u);
		volatile uint32_t *rsd = (volatile uint32_t *)(uintptr_t)(CC3501E_BRIDGE_SPI1_BASE + 0xf0u);
		uint32_t           en  = *ssienr;
		*ssienr                = 0u;
		*rsd                   = (uint32_t)CC3501E_BRIDGE_RX_SAMPLE_DLY;
		*ssienr                = en;
	}
#endif

	/* 3. Bind the bus + control pins; attach the GPIO proxy (proxied E1M IOs then
	 *    route over the bridge); run the power + reset sequence (TI SWRU626 + the
	 *    Puya cold-boot hard-reset workaround).  Leaves WIFI_EN HIGH. */
	(void)cc3501e_init(fw, spi);
	fw->enable_pin = wifi_en;
	fw->reset_pin  = nrst;
	/* READY (CC35 GPIO17) is NOT wired here by default on this R2 module --
	 * see chips/cc3501e/cc3501e_core.c's cc3501e_reply_gate() comment for the
	 * pin-routing fact, the bench evidence, and how a board that genuinely
	 * wires it can opt back in via fw->ready_pin. */
#ifdef CONFIG_ALP_SDK_GPIO_CC3501E_PROXY
	(void)alp_gpio_cc3501e_attach(fw);
#endif
#ifdef CONFIG_ALP_SDK_WIFI_CC3501E
	(void)alp_wifi_cc3501e_attach(fw);
#endif
#ifdef CONFIG_ALP_SDK_BLE_CC3501E
	(void)alp_ble_cc3501e_attach(fw);
#endif
	/* One line naming the path taken, so a log shows whether the supply was cycled. */
	if (!wifi_was_high) {
		printf("[cc3501e_bridge] WIFI_EN low: cold power-up (cc3501e_reset)\n");
		return cc3501e_reset(fw); /* supply low: the full cold-boot sequence */
	}
	/* WIFI_EN reads high.  Warm = the chip ANSWERS a PING; a pull-up alone proves
	 * nothing.  Warm: nRESET only, never a WIFI_EN toggle. */
	if (cc3501e_ping(fw) == ALP_OK) {
		printf("[cc3501e_bridge] WIFI_EN high, PING ok: warm, nRESET only\n");
		return cc3501e_hard_reset(fw);
	}
	/* High but silent: powered-and-hung, or unpowered behind a pull-up.  Try the
	 * nRESET-only reset first (safe for a powered chip); only if the chip still does
	 * not answer is the supply cycled -- the last resort, taken from a chip that is
	 * already unresponsive. */
	if (cc3501e_hard_reset(fw) == ALP_OK && cc3501e_ping(fw) == ALP_OK) {
		printf("[cc3501e_bridge] WIFI_EN high, silent: recovered by nRESET only\n");
		return ALP_OK;
	}
	printf("[cc3501e_bridge] WIFI_EN high, silent after nRESET: supply cycle (cc3501e_reset)\n");
	return cc3501e_reset(fw);
}
```
